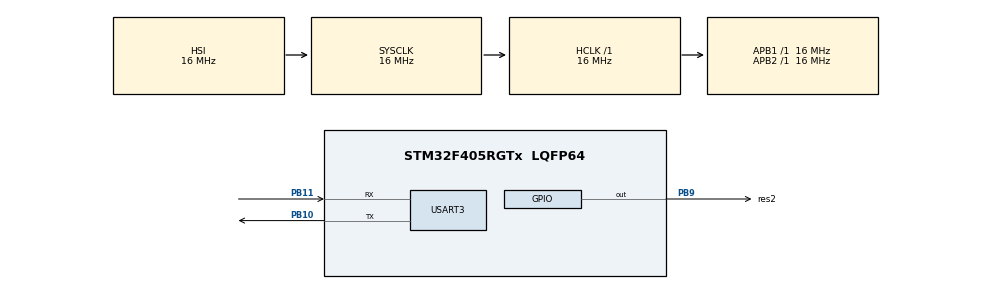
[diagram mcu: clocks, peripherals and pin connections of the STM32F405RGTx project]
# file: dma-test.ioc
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Dma.Request0=USART3_TX
Dma.USART3_TX.0.Direction=DMA_MEMORY_TO_PERIPH
Dma.USART3_TX.0.FIFOMode=DMA_FIFOMODE_DISABLE
Dma.USART3_TX.0.Instance=DMA1_Stream3
Dma.USART3_TX.0.MemDataAlignment=DMA_MDATAALIGN_BYTE
Dma.USART3_TX.0.MemInc=DMA_MINC_ENABLE
Dma.USART3_TX.0.Mode=DMA_NORMAL
Dma.USART3_TX.0.PeriphDataAlignment=DMA_PDATAALIGN_BYTE
Dma.USART3_TX.0.PeriphInc=DMA_PINC_DISABLE
Dma.USART3_TX.0.Priority=DMA_PRIORITY_LOW
Mcu.Family=STM32F4
Mcu.Name=STM32F405RGTx
Mcu.Package=LQFP64
NVIC.DMA1_Stream3_IRQn=true\:0\:0\:false\:false\:true\:false\:true\:true
NVIC.PriorityGroup=NVIC_PRIORITYGROUP_4
NVIC.USART3_IRQn=true\:0\:0\:false\:false\:true\:true\:true\:true
PB10.Mode=Asynchronous
PB10.Signal=USART3_TX
PB11.Mode=Asynchronous
PB11.Signal=USART3_RX
PB9.GPIO_Label=res2
PB9.Signal=GPIO_Output
ProjectManager.HeapSize=0x200
ProjectManager.StackSize=0x400
ProjectManager.TargetToolchain=STM32CubeIDE
RCC.AHBFreq_Value=16000000
RCC.APB1Freq_Value=16000000
RCC.APB2Freq_Value=16000000
RCC.CortexFreq_Value=16000000
RCC.HSE_VALUE=25000000
RCC.HSI_VALUE=16000000
RCC.LSE_VALUE=32768
RCC.SYSCLKFreq_VALUE=16000000
RCC.VCOOutputFreq_Value=192000000
USART3.VirtualMode=VM_ASYNC
board=custom

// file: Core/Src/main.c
/* USER CODE BEGIN Header */
/**
 ******************************************************************************
 * @file           : main.c
 * @brief          : Main program body
 ******************************************************************************
 * @attention
 *
 * Copyright (c) 2022 STMicroelectronics.
 * All rights reserved.
 *
 * This software is licensed under terms that can be found in the LICENSE file
 * in the root directory of this software component.
 * If no LICENSE file comes with this software, it is provided AS-IS.
 *
 ******************************************************************************
 */
/* USER CODE END Header */
#include "main.h"

/* USER CODE BEGIN Includes */
#include <string.h>
/* USER CODE END Includes */

UART_HandleTypeDef huart3;
DMA_HandleTypeDef hdma_usart3_tx;

/* USER CODE BEGIN PV */
char data[1001];
int count = 0;
char ch = 'b';
/* USER CODE END PV */

void SystemClock_Config(void);
static void MX_GPIO_Init(void);
static void MX_DMA_Init(void);
static void MX_USART3_UART_Init(void);

/* USER CODE BEGIN 0 */
//void HAL_UART_TxHalfCpltCallback(UART_HandleTypeDef *huart) {
//	for (int i = 0; i < 1000; i++) {
//		data[i] = 'z';
//	}
//}
void HAL_UART_TxCpltCallback(UART_HandleTypeDef *huart) {
	for (int i = 0; i < 1000; i++) {
		data[i] = ch;
	}
	if (ch == 'z') {
		ch = 'a';
	} else {
		ch++;
	}
}
/* USER CODE END 0 */

int main(void) {

	/* MCU Configuration--------------------------------------------------------*/

	/* Reset of all peripherals, Initializes the Flash interface and the Systick. */
	HAL_Init();

	/* Configure the system clock */
	SystemClock_Config();

	/* Initialize all configured peripherals */
	MX_GPIO_Init();
	MX_DMA_Init();
	MX_USART3_UART_Init();
	/* USER CODE BEGIN 2 */
	for (int i = 0; i < 1000; i++) {
		data[i] = 'a';
	}
	data[1001] = '\0';
	/* USER CODE END 2 */

	/* Infinite loop */
	/* USER CODE BEGIN WHILE */
	while (1) {
		HAL_GPIO_TogglePin(res2_GPIO_Port, res2_Pin);
		HAL_Delay(250);

		count++;

		if ((count % 20) == 0) {
			HAL_UART_Transmit_DMA(&huart3, (uint8_t*) data, strlen(data));
		}
		/* USER CODE END WHILE */

	}
}

void SystemClock_Config(void) {
	RCC_OscInitTypeDef RCC_OscInitStruct = { 0 };
	RCC_ClkInitTypeDef RCC_ClkInitStruct = { 0 };

	/** Configure the main internal regulator output voltage
	 */
	__HAL_RCC_PWR_CLK_ENABLE();
	__HAL_PWR_VOLTAGESCALING_CONFIG(PWR_REGULATOR_VOLTAGE_SCALE1);

	/** Initializes the RCC Oscillators according to the specified parameters
	 * in the RCC_OscInitTypeDef structure.
	 */
	RCC_OscInitStruct.OscillatorType = RCC_OSCILLATORTYPE_HSI;
	RCC_OscInitStruct.HSIState = RCC_HSI_ON;
	RCC_OscInitStruct.HSICalibrationValue = RCC_HSICALIBRATION_DEFAULT;
	RCC_OscInitStruct.PLL.PLLState = RCC_PLL_NONE;
	if (HAL_RCC_OscConfig(&RCC_OscInitStruct) != HAL_OK) {
		Error_Handler();
	}

	/** Initializes the CPU, AHB and APB buses clocks
	 */
	RCC_ClkInitStruct.ClockType = RCC_CLOCKTYPE_HCLK | RCC_CLOCKTYPE_SYSCLK
			| RCC_CLOCKTYPE_PCLK1 | RCC_CLOCKTYPE_PCLK2;
	RCC_ClkInitStruct.SYSCLKSource = RCC_SYSCLKSOURCE_HSI;
	RCC_ClkInitStruct.AHBCLKDivider = RCC_SYSCLK_DIV1;
	RCC_ClkInitStruct.APB1CLKDivider = RCC_HCLK_DIV1;
	RCC_ClkInitStruct.APB2CLKDivider = RCC_HCLK_DIV1;

	if (HAL_RCC_ClockConfig(&RCC_ClkInitStruct, FLASH_LATENCY_0) != HAL_OK) {
		Error_Handler();
	}
}

static void MX_USART3_UART_Init(void) {

	huart3.Instance = USART3;
	huart3.Init.BaudRate = 57600;
	huart3.Init.WordLength = UART_WORDLENGTH_8B;
	huart3.Init.StopBits = UART_STOPBITS_1;
	huart3.Init.Parity = UART_PARITY_NONE;
	huart3.Init.Mode = UART_MODE_TX_RX;
	huart3.Init.HwFlowCtl = UART_HWCONTROL_NONE;
	huart3.Init.OverSampling = UART_OVERSAMPLING_16;
	if (HAL_UART_Init(&huart3) != HAL_OK) {
		Error_Handler();
	}

}

static void MX_DMA_Init(void) {

	/* DMA controller clock enable */
	__HAL_RCC_DMA1_CLK_ENABLE();

	/* DMA interrupt init */
	/* DMA1_Stream3_IRQn interrupt configuration */
	HAL_NVIC_SetPriority(DMA1_Stream3_IRQn, 0, 0);
	HAL_NVIC_EnableIRQ(DMA1_Stream3_IRQn);

}

static void MX_GPIO_Init(void) {
	GPIO_InitTypeDef GPIO_InitStruct = { 0 };

	/* GPIO Ports Clock Enable */
	__HAL_RCC_GPIOB_CLK_ENABLE();

	/*Configure GPIO pin Output Level */
	HAL_GPIO_WritePin(res2_GPIO_Port, res2_Pin, GPIO_PIN_RESET);

	/*Configure GPIO pin : res2_Pin */
	GPIO_InitStruct.Pin = res2_Pin;
	GPIO_InitStruct.Mode = GPIO_MODE_OUTPUT_PP;
	GPIO_InitStruct.Pull = GPIO_NOPULL;
	GPIO_InitStruct.Speed = GPIO_SPEED_FREQ_LOW;
	HAL_GPIO_Init(res2_GPIO_Port, &GPIO_InitStruct);

}

void Error_Handler(void) {
	__disable_irq();
	while (1) {
	}
}
